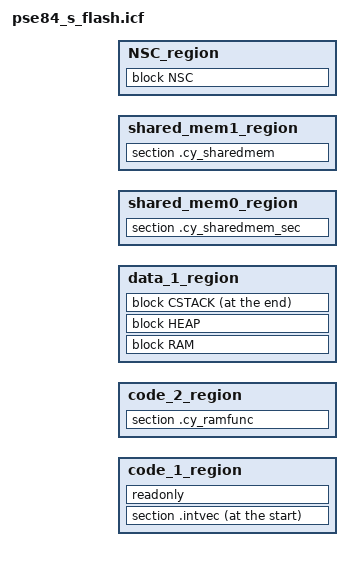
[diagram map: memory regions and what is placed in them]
/***************************************************************************//**
* \file pse84_s_flash.icf
* \version 1.0.0
*
* Linker file for the IAR compiler.
*
* The main purpose of the linker script is to describe how the sections in the
* input files should be mapped into the output file, and to control the memory
* layout of the output file.
*
* \note The entry point location starts at 0x14000000. The valid
* application image should be placed there.
*
* \note The linker files included with the PDL template projects must be generic
* and handle all common use cases. Your project may not use every section
* defined in the linker files. In that case you may see warnings during the
* build process. In your project, you can simply comment out or remove the
* relevant code in the linker file.
*
********************************************************************************
* \copyright
* Copyright (c) (2020-2023), Cypress Semiconductor Corporation (an Infineon company) or
* an affiliate of Cypress Semiconductor Corporation.
* SPDX-License-Identifier: Apache-2.0
*
* Licensed under the Apache License, Version 2.0 (the "License");
* you may not use this file except in compliance with the License.
* You may obtain a copy of the License at
*
*     http://www.apache.org/licenses/LICENSE-2.0
*
* Unless required by applicable law or agreed to in writing, software
* distributed under the License is distributed on an "AS IS" BASIS,
* WITHOUT WARRANTIES OR CONDITIONS OF ANY KIND, either express or implied.
* See the License for the specific language governing permissions and
* limitations under the License.
*******************************************************************************/
include  "pse84_common.icf";

define symbol CODE_XIP0_OFFSET            = XIP0_CM33S_APP_OFFSET;
define symbol CODE_XIP0_VMA               = XIP0_S_CBUS_START + CODE_XIP0_OFFSET;
define symbol CODE_XIP0_LMA               = XIP0_S_SAHB_START + CODE_XIP0_OFFSET;
define symbol CODE_XIP0_SIZE              = XIP0_CM33S_APP_SIZE;

define symbol CODE_SRAM0_OFFSET           = SRAM0_CM33S_APP_OFFSET;
define symbol CODE_SRAM0_VMA              = SRAM0_S_CBUS_START + CODE_SRAM0_OFFSET;
define symbol CODE_SRAM0_LMA              = SRAM0_S_SAHB_START + CODE_SRAM0_OFFSET;
define symbol CODE_SRAM0_SIZE             = SRAM0_CM33S_APP_SIZE;

define symbol CODE_RRAM_OFFSET            = RRAM_CM33S_APP_OFFSET;
define symbol CODE_RRAM_VMA               = RRAM_NVM_MAIN_S_CBUS_START + CODE_RRAM_OFFSET;
define symbol CODE_RRAM_LMA               = RRAM_NVM_MAIN_S_START + CODE_RRAM_OFFSET;
define symbol CODE_RRAM_SIZE              = RRAM_CM33S_APP_SIZE;

define symbol DATA_SRAM0_OFFSET           = SRAM0_CM33S_DATA_OFFSET;
define symbol DATA_SRAM0_VMA              = SRAM0_S_SAHB_START + DATA_SRAM0_OFFSET;
define symbol DATA_SRAM0_LMA              = SRAM0_S_SAHB_START + DATA_SRAM0_OFFSET;
define symbol DATA_SRAM0_SIZE             = SRAM0_CM33S_DATA_SIZE;

define symbol SRAM0_SHARED_LMA            = SRAM0_S_SAHB_START + SRAM0_SHARED_OFFSET + SRAM0_SHARED_CM0_SIZE;
define symbol SRAM0_SHARED_CM33_SIZE      = SRAM0_SHARED_SIZE - SRAM0_SHARED_CM0_SIZE;

define symbol SRAM1_SHARED_LMA            = SRAM1_S_SAHB_START + SRAM1_SIZE - SRAM1_SHARED_SIZE;

define symbol RAMVECTORS_ALIGNMENT        = CM33_RAMVECTORS_ALIGNMENT;
/* define symbol MSP_STACK_SIZE              = CM33S_MSP_STACK_SIZE; */
/*----------------------------------------*/
define symbol CODE_1_VMA                 = CODE_XIP0_VMA;
define symbol CODE_1_LMA                 = CODE_XIP0_LMA;
define symbol CODE_1_SIZE                = CODE_XIP0_SIZE;
define symbol CODE_NSC_VMA               = CODE_1_VMA + CODE_1_SIZE;
define symbol CODE_NSC_LMA               = CODE_1_LMA + CODE_1_SIZE;

define symbol CODE_2_VMA                 = CODE_SRAM0_VMA;
define symbol CODE_2_LMA                 = CODE_SRAM0_LMA;
define symbol CODE_2_SIZE                = CODE_SRAM0_SIZE;

define symbol CODE_3_VMA                 = CODE_RRAM_VMA;
define symbol CODE_3_LMA                 = CODE_RRAM_LMA;
define symbol CODE_3_SIZE                = CODE_RRAM_SIZE;

define symbol DATA_1_VMA                 = DATA_SRAM0_VMA;
define symbol DATA_1_LMA                 = DATA_SRAM0_LMA;
define symbol DATA_1_SIZE                = DATA_SRAM0_SIZE;

define symbol SHARED_MEM0_LMA            = SRAM0_SHARED_LMA;
define symbol SHARED_MEM0_VMA            = SRAM0_SHARED_LMA;
define symbol SHARED_MEM0_SIZE           = SRAM0_SHARED_CM33_SIZE;

define symbol SHARED_MEM1_LMA            = SRAM1_SHARED_LMA;
define symbol SHARED_MEM1_VMA            = SRAM1_SHARED_LMA;
define symbol SHARED_MEM1_SIZE           = SRAM1_SHARED_CM33S_SIZE;

define symbol __app_text2_vma__          = CODE_2_VMA;
define symbol __app_text3_vma__          = CODE_3_VMA;

define symbol  __data1_vma__             = DATA_1_VMA;

/* To set stack size in application add makefile ldflags: --config_def APP_MSP_STACK_SIZE=0x00001000 */
if (!isdefinedsymbol(APP_MSP_STACK_SIZE)) {
  define symbol APP_MSP_STACK_SIZE   = CM33S_MSP_STACK_SIZE;
}

define symbol __ICFEDIT_size_cstack__ = APP_MSP_STACK_SIZE;
define symbol __ICFEDIT_size_heap__ = HEAP_SIZE;

/*-----------------------------------------------------------------------------------*/
define memory mem with size = 4G;

define region code_1_region = mem:[from CODE_1_VMA to CODE_1_VMA + CODE_1_SIZE];
define region code_2_region = mem:[from CODE_2_LMA to CODE_2_LMA + CODE_2_SIZE];
define region data_1_region = mem:[from DATA_1_VMA to DATA_1_VMA + DATA_1_SIZE];
define region shared_mem0_region =  mem:[from SHARED_MEM0_LMA to SHARED_MEM0_LMA + SHARED_MEM0_SIZE]; /* shared_ram0 */
define region shared_mem1_region =  mem:[from SHARED_MEM1_LMA to SHARED_MEM1_LMA + SHARED_MEM1_SIZE]; /* shared_ram1 */
define region NSC_region  =   mem:[from CODE_NSC_VMA to CODE_NSC_VMA + CODE_NSC_SIZE];
define block CSTACK     with alignment = 8, size = __ICFEDIT_size_cstack__ { };
define block HEAP       with expanding size, alignment = 8, minimum size = __ICFEDIT_size_heap__ { };

define block RAM_DATA {readwrite section .data};
define block RAM_OTHER {readwrite section * };
define block RAM_NOINIT {readwrite section .noinit};
define block RAM_BSS {readwrite section .bss};
define block RAM with fixed order {block RAM_DATA, block RAM_OTHER, block RAM_NOINIT, block RAM_BSS};
define block NSC      with alignment = 4, fixed order {section Veneer$$CMSE};

/*-Initializations-*/
initialize by copy { readwrite };
do not initialize  { section .noinit, section .intvec_ram };

place at start of code_1_region  { section .intvec };
place in          code_1_region  { readonly };

place in  NSC_region { block NSC };

place in          code_2_region  { section .cy_ramfunc };

place in          data_1_region  {  block RAM,
                                    block HEAP };
place at end   of data_1_region  { block CSTACK };

place in          shared_mem0_region { section .cy_sharedmem_sec };

place in          shared_mem1_region { section .cy_sharedmem };

keep {  section .intvec  };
